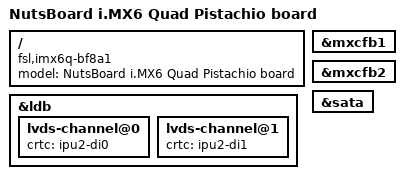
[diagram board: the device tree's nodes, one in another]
/*
 * Copyright 2017 NutsBoard.Org
 * Copyright 2012=2015 Freescale Semiconductor, Inc.
 * Copyright 2011 Linaro Ltd.
 *
 * The code contained herein is licensed under the GNU General Public
 * License. You may obtain a copy of the GNU General Public License
 * Version 2 or later at the following locations:
 *
 * http://www.opensource.org/licenses/gpl-license.html
 * http://www.gnu.org/copyleft/gpl.html
 */

/dts-v1/;

#include "imx6q.dtsi"
#include "imx6qdl-pistachio.dtsi"

/ {
	model = "NutsBoard i.MX6 Quad Pistachio board";
	compatible = "fsl,imx6q-bf8a1", "fsl,imx6q";
};


&ldb {
	lvds-channel@0 {
		crtc = "ipu2-di0";
	};

	lvds-channel@1 {
		crtc = "ipu2-di1";
	};
};

&mxcfb1 {
	status = "okay";
};

&mxcfb2 {
	status = "okay";
};

&sata {
	status = "okay";
};
